# SCnSCB_356.0 register map
Vendor: Texas Instruments
Peripheral module from a debugger description file (folder MSP432).
Registers are 32-bit, read-only, no defined reset value unless marked. A register's access mark holds for its fields unless they carry their own. Offsets are as the file gives them; lines under a group give offsets from that group; [hi:lo] are bit positions; {n}, {i} and the like mark numbered series; 'fields as' and 'values as' point back to an identical list; <NAME> marks a mode.

## SCnSCB
0x04 ICTR — Interrupt Control Type Register
  [4:0] INTLINESNUM — Total number of interrupt lines in groups of 32.
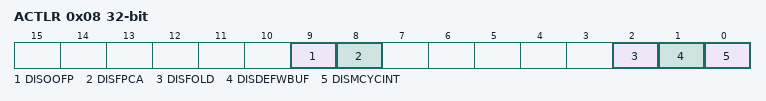
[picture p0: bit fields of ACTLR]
0x08 ACTLR rw — Auxiliary Control Register
  [9] DISOOFP — Disables floating point instructions completing out of order with respect to integer instructions.
  [8] DISFPCA — Disable automatic update of CONTROL.FPCA
  [2] DISFOLD — Disables IT folding.
  [1] DISDEFWBUF — Disables write buffer us during default memorty map accesses. This causes all bus faults to be precise bus faults but decreases the performance of the processor because the stores to memory have to complete before the next instruction can be executed.
  [0] DISMCYCINT — Disables interruption of multi-cycle instructions. This increases the interrupt latency of the processor becuase LDM/STM completes before interrupt stacking occurs.
